VERSION ""

NS_ :

BS_:

BU_: Others VCU
VAL_TABLE_ TMSTATUS1_6B7_Hill_Stop 1 "enable" 0 "disable" ;
VAL_TABLE_ VCUTMComd_0B35_Current_Gear 4 "空挡" 2 "倒挡" 1 "前进挡" ;
VAL_TABLE_ VCUTMComd_0B2_Foot_Brake 1 "有效" 0 "无效" ;
VAL_TABLE_ VCUTMComd_0B1_HandBrake 1 "有效" 0 "无效" ;
VAL_TABLE_ TMSTATUS2_7B_TMState 511 "无效" 254 "异常" 4 "准备状态" 3 "关闭状态" 2 "发电" 1 "耗电" ;
VAL_TABLE_ TMSTATUS2_6B03_TMFailGrade 4 "严重故障" 3 "比较严重故障" 2 "故障" 1 "警告故障" 0 "无故障" ;
VAL_TABLE_ TMSTATUS1_7B03_TMMCUWorkMode 8 "错误" 7 "下弱电" 6 "主动放电" 5 "电机转矩闭环运行" 4 "电机转速闭环运行" 3 "电机允许运行" 2 "预留" 1 "低压上电正常" 0 "初始化" ;
VAL_TABLE_ TMSTATUS1_6B6_TMIGBTEnable 1 "enable" 0 "disable" ;
VAL_TABLE_ TMSTATUS1_6B5_TMActiveDisCharge 1 "enable" 0 "disable" ;
VAL_TABLE_ TMSTATUS1_6B4_TMPrechargeAllow 1 "enable" 0 "disable" ;
VAL_TABLE_ VCUTMComd_1B23_TMWorkMode 17 "Active DisCharge" 16 "TorQue Control" 1 "Speed Control" 0 "Standby" ;
VAL_TABLE_ VCUTMComd_1B1_TMFaultReset 1 "enable" 0 "disable" ;
VAL_TABLE_ VCUTMComd_1B0_TMMCUEnable 1 "enable" 0 "disable" ;
VAL_TABLE_ VCUTMComd_0B67_TMCtrlMode 17 "Description for the value '0x1F'" 16 "Braking" 1 "Drive" 0 "Free" ;
VAL_TABLE_ RefOrd_2B_TMProINF 1 "ON_Refer" 0 "OFF_Refer" ;
VAL_TABLE_ RefOrd_0B1_TMProductionINF 1 "ON_Refer" 0 "OFF_Refer" ;
VAL_TABLE_ TMProMsg2_67B_RatedPower 65535 "无效" 65534 "异常" ;
VAL_TABLE_ TMProMsg2_45B_RatedTorq 65535 "无效" 65534 "异常" ;
VAL_TABLE_ TMProMsg2_23B_PeakTorq 65535 "无效" 65534 "异常" ;
VAL_TABLE_ TMProMsg2_01B_TMMaxSpd 65535 "无效" 65534 "异常" ;
VAL_TABLE_ TMProMsg1_6B_TypeOfCooling 255 "其他方式" 2 "风冷" 1 "水冷" ;
VAL_TABLE_ TMProMsg1_45B_PeakPower 65535 "无效" 65534 "异常" ;
VAL_TABLE_ TMProMsg1_23B_MaxWorkingCur 65535 "无效" 65534 "异常" ;
VAL_TABLE_ TMProMsg1_01B_RatedVoltage 65535 "无效" 65534 "异常" ;

BO_ 3221225472 VECTOR__INDEPENDENT_SIG_MSG: 0 Vector__XXX
 SG_ RefOrd_0B1_Data_valid_Flag : 0|1@1+ (1,0) [0|0] "" Vector__XXX
 SG_ RefOrd_37B_Reserve : 0|40@1+ (1,0) [0|0] "" Vector__XXX
 SG_ RefOrd_1B : 0|8@1+ (1,0) [0|0] "" Vector__XXX
 SG_ SAS1_1B_SAS_Steering_Angle_HByte : 0|8@1+ (1,0) [0|0] "" Vector__XXX

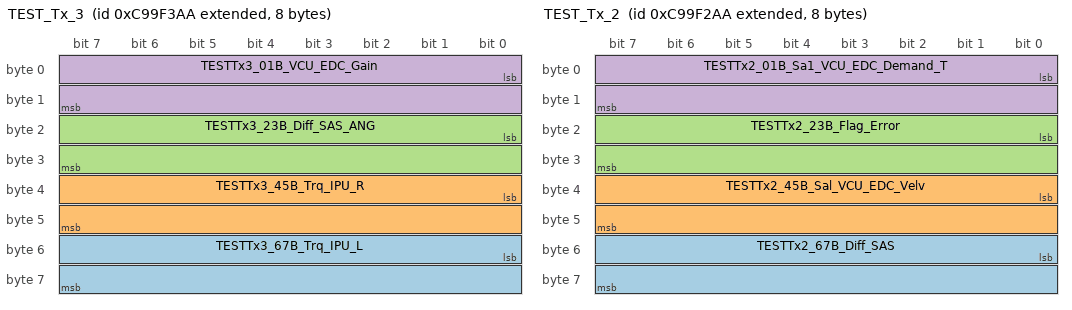
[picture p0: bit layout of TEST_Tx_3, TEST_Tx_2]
BO_ 2358899626 TEST_Tx_3: 8 Others
 SG_ TESTTx3_67B_Trq_IPU_L : 48|16@1+ (1,-5000) [0|0] "" Vector__XXX
 SG_ TESTTx3_45B_Trq_IPU_R : 32|16@1+ (1,-5000) [0|0] "" Vector__XXX
 SG_ TESTTx3_23B_Diff_SAS_ANG : 16|16@1- (1,0) [0|0] "" Vector__XXX
 SG_ TESTTx3_01B_VCU_EDC_Gain : 0|16@1+ (0.01,0) [0|0] "" Vector__XXX

BO_ 2358899370 TEST_Tx_2: 8 Others
 SG_ TESTTx2_67B_Diff_SAS : 48|16@1+ (1,0) [0|0] "" Vector__XXX
 SG_ TESTTx2_45B_Sal_VCU_EDC_Velv : 32|16@1+ (0.1,0) [0|0] "" Vector__XXX
 SG_ TESTTx2_23B_Flag_Error : 16|16@1+ (1,0) [0|0] "" Vector__XXX
 SG_ TESTTx2_01B_Sa1_VCU_EDC_Demand_T : 0|16@1+ (1,0) [0|0] "" Vector__XXX

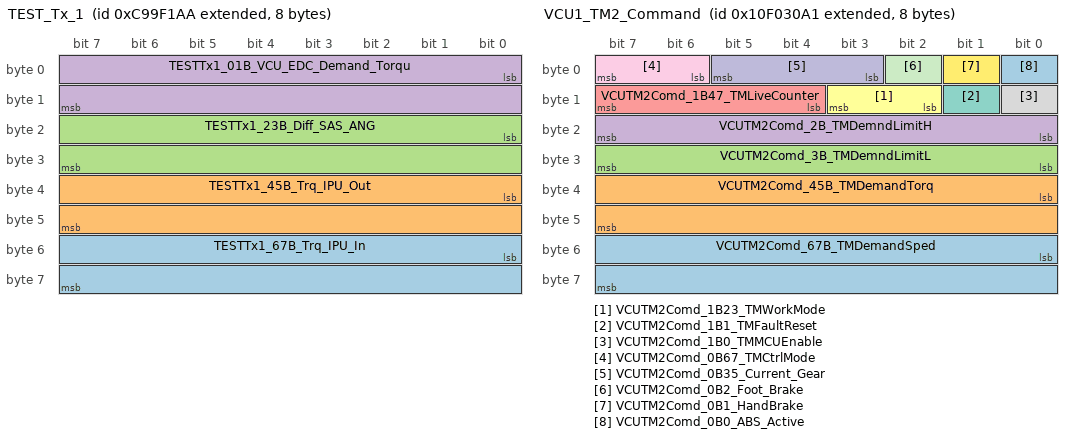
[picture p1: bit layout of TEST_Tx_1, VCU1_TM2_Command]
BO_ 2358899114 TEST_Tx_1: 8 Others
 SG_ TESTTx1_67B_Trq_IPU_In : 48|16@1- (1,0) [0|0] "" Vector__XXX
 SG_ TESTTx1_45B_Trq_IPU_Out : 32|16@1- (1,0) [0|0] "" Vector__XXX
 SG_ TESTTx1_23B_Diff_SAS_ANG : 16|16@1+ (1,0) [0|0] "" Vector__XXX
 SG_ TESTTx1_01B_VCU_EDC_Demand_Torqu : 0|16@1- (1,0) [0|0] "" Vector__XXX

BO_ 2431660193 VCU1_TM2_Command: 8 VCU
 SG_ VCUTM2Comd_67B_TMDemandSped : 48|16@1+ (1,-15000) [-15000|15000] "" Vector__XXX
 SG_ VCUTM2Comd_45B_TMDemandTorq : 32|16@1+ (1,-5000) [-5000|5000] "" Vector__XXX
 SG_ VCUTM2Comd_3B_TMDemndLimitL : 24|8@1+ (20,0) [0|5000] "rpm" Vector__XXX
 SG_ VCUTM2Comd_2B_TMDemndLimitH : 16|8@1+ (20,0) [0|5000] "rpm" Vector__XXX
 SG_ VCUTM2Comd_1B47_TMLiveCounter : 12|4@1+ (1,0) [0|0] "" Vector__XXX
 SG_ VCUTM2Comd_1B23_TMWorkMode : 10|2@1+ (1,0) [0|0] "" Vector__XXX
 SG_ VCUTM2Comd_1B1_TMFaultReset : 9|1@1+ (1,0) [0|0] "" Vector__XXX
 SG_ VCUTM2Comd_1B0_TMMCUEnable : 8|1@1+ (1,0) [0|0] "" Vector__XXX
 SG_ VCUTM2Comd_0B67_TMCtrlMode : 6|2@1+ (1,0) [0|0] "" Vector__XXX
 SG_ VCUTM2Comd_0B35_Current_Gear : 3|3@1+ (1,0) [0|0] "" Vector__XXX
 SG_ VCUTM2Comd_0B2_Foot_Brake : 2|1@1+ (1,0) [0|0] "" Vector__XXX
 SG_ VCUTM2Comd_0B1_HandBrake : 1|1@1+ (1,0) [0|0] "" Vector__XXX
 SG_ VCUTM2Comd_0B0_ABS_Active : 0|1@1+ (1,0) [0|0] "" Vector__XXX

BO_ 2565878949 TM2_STATUS_4: 8 Others
 SG_ TM2STATUS4_23B15_Inside_LVPower_ : 31|1@1+ (1,0) [0|0] "" Vector__XXX
 SG_ TM2STATUS4_23B14_Inverter_TS_War : 30|1@1+ (1,0) [0|0] "" Vector__XXX
 SG_ TM2STATUS4_23B13_Winding_TS_Warn : 29|1@1+ (1,0) [0|0] "" Vector__XXX
 SG_ TM2STATUS5_7B_MCUCode : 56|8@1+ (1,0) [0|0] "" Vector__XXX
 SG_ TM2STATUS4_5B0_Compel_field_weak : 40|1@1+ (1,0) [0|0] "" Vector__XXX
 SG_ TM2STATUS4_4B3_StallTemper_Torqu : 35|1@1+ (1,0) [0|0] "" Vector__XXX
 SG_ TM2STATUS4_4B2_ModuleTemper_Torq : 34|1@1+ (1,0) [0|0] "" Vector__XXX
 SG_ TM2STATUS4_4B1_MotorTemper_Torqu : 33|1@1+ (1,0) [0|0] "" Vector__XXX
 SG_ TM2STATUS4_4B0_HSpeed_TorqueLimi : 32|1@1+ (1,0) [0|0] "" Vector__XXX
 SG_ TM2STATUS4_23B9_EEPROM_Error : 25|1@1+ (1,0) [0|0] "" Vector__XXX
 SG_ TM2STATUS4_23B8_DC_Hall_Error : 24|1@1+ (1,0) [0|0] "" Vector__XXX
 SG_ TM2STATUS4_23B7_RDC_Dos_Warnning : 23|1@1+ (1,0) [0|0] "" Vector__XXX
 SG_ TM2STATUS4_23B6_RDC_Lot_Warnning : 22|1@1+ (1,0) [0|0] "" Vector__XXX
 SG_ TM2STATUS4_23B5_Output_ShortCut_ : 21|1@1+ (1,0) [0|0] "" Vector__XXX
 SG_ TM2STATUS4_23B4_OverLoad_Warnnin : 20|1@1+ (1,0) [0|0] "" Vector__XXX
 SG_ TM2STATUS4_23B3_Rotor_Lock_Warnn : 19|1@1+ (1,0) [0|0] "" Vector__XXX
 SG_ TM2STATUS4_23B2_Speed_High_Warnn : 18|1@1+ (1,0) [0|0] "" Vector__XXX
 SG_ TM2STATUS4_23B1_IGBT_Temp_Warnni : 17|1@1+ (1,0) [0|0] "" Vector__XXX
 SG_ TM2STATUS4_23B12_Bus_LV_Warning : 28|1@1+ (1,0) [0|0] "" Vector__XXX
 SG_ TM2STATUS4_23B11_Bus_OV_Warning : 27|1@1+ (1,0) [0|0] "" Vector__XXX
 SG_ TM2STATUS4_23B10_LowPowerSupply_ : 26|1@1+ (1,0) [0|0] "" Vector__XXX
 SG_ TM2STATUS4_23B0_Motor_Temp_Warnn : 16|1@1+ (1,0) [0|0] "" Vector__XXX
 SG_ TM2STATUS4_01B9_Bus_LV_Fault : 15|1@1+ (1,0) [0|0] "" Vector__XXX
 SG_ TM2STATUS4_01B8_Bus_OV_Fault : 14|1@1+ (1,0) [0|0] "" Vector__XXX
 SG_ TM2STATUS4_01B7_RDC_Fault : 13|1@1+ (1,0) [0|0] "" Vector__XXX
 SG_ TM2STATUS4_01B6_LosePhase_Fault : 12|1@1+ (1,0) [0|0] "" Vector__XXX
 SG_ TM2STATUS4_01B5_IGBT_W_Fault : 11|1@1+ (1,0) [0|0] "" Vector__XXX
 SG_ TM2STATUS4_01B4_IGBT_V_Fault : 10|1@1+ (1,0) [0|0] "" Vector__XXX
 SG_ TM2STATUS4_01B3_IGBT_U_Fault : 9|1@1+ (1,0) [0|0] "" Vector__XXX
 SG_ TM2STATUS4_01B2_Output_Over_Curr : 8|1@1+ (1,0) [0|0] "" Vector__XXX
 SG_ TM2STATUS4_01B1_HD_Driver_OC : 7|1@1+ (1,0) [0|0] "" Vector__XXX
 SG_ TM2STATUS4_01B15_Can_Error : 6|1@1+ (1,0) [0|0] "" Vector__XXX
 SG_ TM2STATUS4_01B14_AC_Hall_Fault : 5|1@1+ (1,0) [0|0] "" Vector__XXX
 SG_ TM2STATUS4_01B13_Water_Over_Temp : 4|1@1+ (1,0) [0|0] "" Vector__XXX
 SG_ TM2STATUS4_01B12_IGBT_Over_Temp : 3|1@1+ (1,0) [0|0] "" Vector__XXX
 SG_ TM2STATUS4_01B11_Motor_Over_Temp : 2|1@1+ (1,0) [0|0] "" Vector__XXX
 SG_ TM2STATUS4_01B10_Over_Speed : 1|1@1+ (1,0) [0|0] "" Vector__XXX
 SG_ TM2STATUS4_01B0_HD_Driver_Fault : 0|1@1+ (1,0) [0|0] "" Vector__XXX

BO_ 2565878693 TM2_STATUS_3: 8 Others
 SG_ TM2STATUS3_7B_TMErrorCode : 56|8@1+ (1,0) [0|0] "" Vector__XXX
 SG_ TM2STATUS3_6B_TMMotRotaCount : 48|8@1+ (1,0) [0|0] "" Vector__XXX
 SG_ TM2STATUS3_45B_TMMCUBUSVol : 32|16@1+ (0.1,0) [0|0] "" Vector__XXX
 SG_ TM2STATUS3_23B_TMMCUBUSCur : 16|16@1+ (0.1,-800) [0|0] "" Vector__XXX
 SG_ TM2STATUS3_1B7_Reserve : 15|1@1+ (1,0) [0|0] "" Vector__XXX
 SG_ TM2STATUS3_1B6_TMWarnOV : 14|1@1+ (1,0) [0|0] "" Vector__XXX
 SG_ TM2STATUS3_1B5_TMWarnUV : 13|1@1+ (1,0) [0|0] "" Vector__XXX
 SG_ TM2STATUS3_1B4_TMWarnWindOT : 12|1@1+ (1,0) [0|0] "" Vector__XXX
 SG_ TM2STATUS3_1B3_TMEWarnInerOt : 11|1@1+ (1,0) [0|0] "" Vector__XXX
 SG_ TM2STATUS3_1B2_TMError24VUV : 10|1@1+ (1,0) [0|0] "" Vector__XXX
 SG_ TM2STATUS3_1B1_TMErrorUV : 9|1@1+ (1,0) [0|0] "" Vector__XXX
 SG_ TM2STATUS3_1B0_TMErrorITM : 8|1@1+ (1,0) [0|0] "" Vector__XXX
 SG_ TM2STATUS3_0B7_TMErrorCAN : 7|1@1+ (1,0) [0|0] "" Vector__XXX
 SG_ TM2STATUS3_0B6_TMErrorWindingTS : 6|1@1+ (1,0) [0|0] "" Vector__XXX
 SG_ TM2STATUS3_0B5_TMErrorResolver : 5|1@1+ (1,0) [0|0] "" Vector__XXX
 SG_ TM2STATUS3_0B4_TMErrorInverterOT : 4|1@1+ (1,0) [0|0] "" Vector__XXX
 SG_ TM2STATUS3_0B3_TMErrorWindingOT : 3|1@1+ (1,0) [0|0] "" Vector__XXX
 SG_ TM2STATUS3_0B2_TMError0S : 2|1@1+ (1,0) [0|0] "" Vector__XXX
 SG_ TM2STATUS3_0B1_TMError0C : 1|1@1+ (1,0) [0|0] "" Vector__XXX
 SG_ TM2STATUS3_0B0_TMError0V : 0|1@1+ (1,0) [0|0] "" Vector__XXX

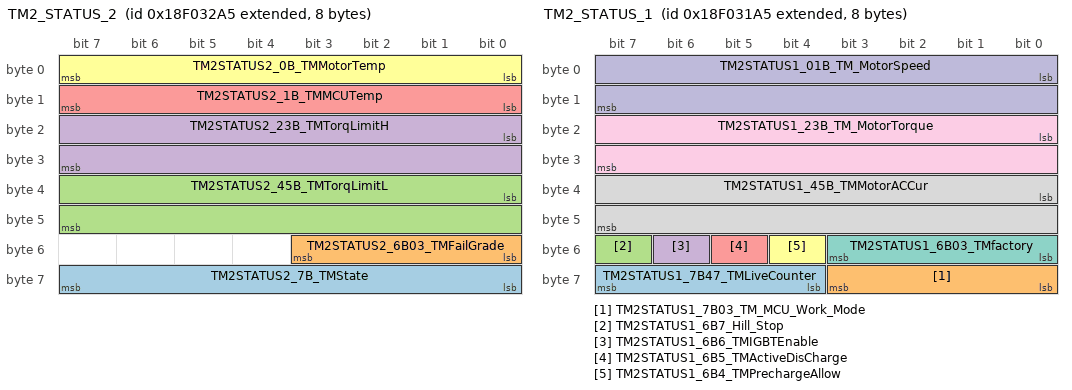
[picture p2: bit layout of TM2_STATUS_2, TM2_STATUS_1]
BO_ 2565878437 TM2_STATUS_2: 8 Others
 SG_ TM2STATUS2_7B_TMState : 56|8@1+ (1,0) [0|0] "" Vector__XXX
 SG_ TM2STATUS2_6B03_TMFailGrade : 48|4@1+ (1,0) [0|0] "" Vector__XXX
 SG_ TM2STATUS2_45B_TMTorqLimitL : 32|16@1+ (1,-5000) [0|0] "" Vector__XXX
 SG_ TM2STATUS2_23B_TMTorqLimitH : 16|16@1+ (1,0) [0|5000] "" Vector__XXX
 SG_ TM2STATUS2_1B_TMMCUTemp : 8|8@1+ (1,-40) [0|0] "" Vector__XXX
 SG_ TM2STATUS2_0B_TMMotorTemp : 0|8@1+ (1,-40) [0|0] "" Vector__XXX

BO_ 2565878181 TM2_STATUS_1: 8 Others
 SG_ TM2STATUS1_7B47_TMLiveCounter : 60|4@1+ (1,0) [0|15] "" Vector__XXX
 SG_ TM2STATUS1_7B03_TM_MCU_Work_Mode : 56|4@1+ (1,0) [0|0] "" Vector__XXX
 SG_ TM2STATUS1_6B7_Hill_Stop : 55|1@1+ (1,0) [0|0] "" Vector__XXX
 SG_ TM2STATUS1_6B6_TMIGBTEnable : 54|1@1+ (1,0) [0|0] "" Vector__XXX
 SG_ TM2STATUS1_6B5_TMActiveDisCharge : 53|1@1+ (1,0) [0|0] "" Vector__XXX
 SG_ TM2STATUS1_6B4_TMPrechargeAllow : 52|1@1+ (1,0) [0|0] "" Vector__XXX
 SG_ TM2STATUS1_6B03_TMfactory : 48|4@1+ (1,0) [0|0] "" Vector__XXX
 SG_ TM2STATUS1_45B_TMMotorACCur : 32|16@1+ (0.1,0) [0|0] "A" Vector__XXX
 SG_ TM2STATUS1_23B_TM_MotorTorque : 16|16@1+ (1,-5000) [0|0] "" Vector__XXX
 SG_ TM2STATUS1_01B_TM_MotorSpeed : 0|16@1+ (1,-15000) [0|0] "" Vector__XXX

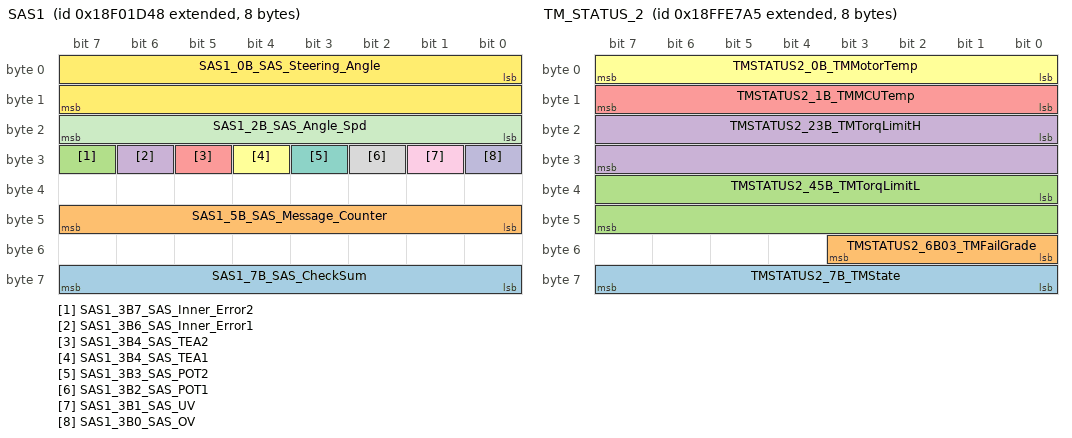
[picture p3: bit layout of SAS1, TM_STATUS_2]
BO_ 2565872968 SAS1: 8 Others
 SG_ SAS1_7B_SAS_CheckSum : 56|8@1+ (1,0) [0|255] "" Vector__XXX
 SG_ SAS1_5B_SAS_Message_Counter : 40|8@1+ (1,0) [0|0] "" Vector__XXX
 SG_ SAS1_3B7_SAS_Inner_Error2 : 31|1@1+ (1,0) [0|0] "" Vector__XXX
 SG_ SAS1_3B6_SAS_Inner_Error1 : 30|1@1+ (1,0) [0|0] "" Vector__XXX
 SG_ SAS1_3B4_SAS_TEA2 : 29|1@1+ (1,0) [0|0] "" Vector__XXX
 SG_ SAS1_3B4_SAS_TEA1 : 28|1@1+ (1,0) [0|0] "" Vector__XXX
 SG_ SAS1_3B3_SAS_POT2 : 27|1@1+ (1,0) [0|0] "" Vector__XXX
 SG_ SAS1_3B2_SAS_POT1 : 26|1@1+ (1,0) [0|0] "" Vector__XXX
 SG_ SAS1_3B1_SAS_UV : 25|1@1+ (1,0) [0|0] "" Vector__XXX
 SG_ SAS1_3B0_SAS_OV : 24|1@1+ (1,0) [0|0] "" Vector__XXX
 SG_ SAS1_2B_SAS_Angle_Spd : 16|8@1+ (4,0) [0|1020] "" Vector__XXX
 SG_ SAS1_0B_SAS_Steering_Angle : 0|16@1- (0.1,0) [0|0] "" Vector__XXX

BO_ 2566908325 TM_STATUS_4: 8 Others
 SG_ TMSTATUS4_23B15_Inside_LVPower_E : 31|1@1+ (1,0) [0|0] "" Vector__XXX
 SG_ TMSTATUS4_23B14_Inverter_TS_Warn : 30|1@1+ (1,0) [0|0] "" Vector__XXX
 SG_ TMSTATUS4_23B13_Winding_TS_Warni : 29|1@1+ (1,0) [0|0] "" Vector__XXX
 SG_ TMSTATUS4_7B_MCUCode : 56|8@1+ (1,0) [0|0] "" Vector__XXX
 SG_ TMSTATUS4_5B0_Compel_field_weake : 40|1@1+ (1,0) [0|0] "" Vector__XXX
 SG_ TMSTATUS4_4B3_StallTemper_Torque : 35|1@1+ (1,0) [0|0] "" Vector__XXX
 SG_ TMSTATUS4_4B2_ModuleTemper_Torqu : 34|1@1+ (1,0) [0|0] "" Vector__XXX
 SG_ TMSTATUS4_4B1_MotorTemper_Torque : 33|1@1+ (1,0) [0|0] "" Vector__XXX
 SG_ TMSTATUS4_4B0_HSpeed_TorqueLimit : 32|1@1+ (1,0) [0|0] "" Vector__XXX
 SG_ TMSTATUS4_23B9_EEPROM_Error : 25|1@1+ (1,0) [0|0] "" Vector__XXX
 SG_ TMSTATUS4_23B8_DC_Hall_Error : 24|1@1+ (1,0) [0|0] "" Vector__XXX
 SG_ TMSTATUS4_23B7_RDC_Dos_Warnning : 23|1@1+ (1,0) [0|0] "" Vector__XXX
 SG_ TMSTATUS4_23B6_RDC_Lot_Warnning : 22|1@1+ (1,0) [0|0] "" Vector__XXX
 SG_ TMSTATUS4_23B5_Output_ShortCut_W : 21|1@1+ (1,0) [0|0] "" Vector__XXX
 SG_ TMSTATUS4_23B4_OverLoad_Warnning : 20|1@1+ (1,0) [0|0] "" Vector__XXX
 SG_ TMSTATUS4_23B3_Rotor_Lock_Warnni : 19|1@1+ (1,0) [0|0] "" Vector__XXX
 SG_ TMSTATUS4_23B2_Speed_High_Warnni : 18|1@1+ (1,0) [0|0] "" Vector__XXX
 SG_ TMSTATUS4_23B1_IGBT_Temp_Warnnin : 17|1@1+ (1,0) [0|0] "" Vector__XXX
 SG_ TMSTATUS4_23B12_Bus_LV_Warning : 28|1@1+ (1,0) [0|0] "" Vector__XXX
 SG_ TMSTATUS4_23B11_Bus_OV_Warning : 27|1@1+ (1,0) [0|0] "" Vector__XXX
 SG_ TMSTATUS4_23B10_LowPowerSupply_E : 26|1@1+ (1,0) [0|0] "" Vector__XXX
 SG_ TMSTATUS4_23B0_Motor_Temp_Warnni : 16|1@1+ (1,0) [0|0] "" Vector__XXX
 SG_ TMSTATUS4_01B9_Bus_LV_Fault : 9|1@1+ (1,0) [0|0] "" Vector__XXX
 SG_ TMSTATUS4_01B8_Bus_OV_Fault : 8|1@1+ (1,0) [0|0] "" Vector__XXX
 SG_ TMSTATUS4_01B7_RDC_Fault : 7|1@1+ (1,0) [0|0] "" Vector__XXX
 SG_ TMSTATUS4_01B6_LosePhase_Fault : 6|1@1+ (1,0) [0|0] "" Vector__XXX
 SG_ TMSTATUS4_01B5_IGBT_W_Fault : 5|1@1+ (1,0) [0|0] "" Vector__XXX
 SG_ TMSTATUS4_01B4_IGBT_V_Fault : 4|1@1+ (1,0) [0|0] "" Vector__XXX
 SG_ TMSTATUS4_01B3_IGBT_U_Fault : 3|1@1+ (1,0) [0|0] "" Vector__XXX
 SG_ TMSTATUS4_01B2_Output_Over_Curre : 2|1@1+ (1,0) [0|0] "" Vector__XXX
 SG_ TMSTATUS4_01B1_HD_Driver_OC : 1|1@1+ (1,0) [0|0] "" Vector__XXX
 SG_ TMSTATUS4_01B15_Can_Error : 15|1@1+ (1,0) [0|0] "" Vector__XXX
 SG_ TMSTATUS4_01B14_AC_Hall_Fault : 14|1@1+ (1,0) [0|0] "" Vector__XXX
 SG_ TMSTATUS4_01B13_Water_Over_Temp : 13|1@1+ (1,0) [0|0] "" Vector__XXX
 SG_ TMSTATUS4_01B12_IGBT_Over_Temp : 12|1@1+ (1,0) [0|0] "" Vector__XXX
 SG_ TMSTATUS4_01B11_Motor_Over_Temp : 11|1@1+ (1,0) [0|0] "" Vector__XXX
 SG_ TMSTATUS4_01B10_Over_Speed : 10|1@1+ (1,0) [0|0] "" Vector__XXX
 SG_ TMSTATUS4_01B0_HD_Driver_Fault : 0|1@1+ (1,0) [0|0] "" Vector__XXX

BO_ 2566908069 TM_STATUS_3: 8 Others
 SG_ TMSTATUS3_0B2_TMError0S : 2|1@1+ (1,0) [0|0] "" Vector__XXX
 SG_ TMSTATUS3_7B_TMErrorCode : 56|8@1+ (1,0) [0|0] "" Vector__XXX
 SG_ TMSTATUS3_6B_TMMotRotaCount : 48|8@1+ (1,0) [0|0] "" Vector__XXX
 SG_ TMSTATUS3_45B_TMMCUBUSVol : 32|16@1+ (0.1,0) [0|0] "" Vector__XXX
 SG_ TMSTATUS3_23B_TMMCUBUSCur : 16|16@1- (0.1,-800) [0|0] "" Vector__XXX
 SG_ TMSTATUS3_1B7_Reserve : 15|1@1+ (1,0) [0|0] "" Vector__XXX
 SG_ TMSTATUS3_1B6_TMWarnOV : 14|1@1+ (1,0) [0|0] "" Vector__XXX
 SG_ TMSTATUS3_1B5_TMWarnUV : 13|1@1+ (1,0) [0|0] "" Vector__XXX
 SG_ TMSTATUS3_1B4_TMWarnWindOT : 12|1@1+ (1,0) [0|0] "" Vector__XXX
 SG_ TMSTATUS3_1B3_TMEWarnInerOt : 11|1@1+ (1,0) [0|0] "" Vector__XXX
 SG_ TMSTATUS3_1B2_TMError24VUV : 10|1@1+ (1,0) [0|0] "" Vector__XXX
 SG_ TMSTATUS3_1B1_TMErrorUV : 9|1@1+ (1,0) [0|0] "" Vector__XXX
 SG_ TMSTATUS3_1B0_TMErrorITM : 8|1@1+ (1,0) [0|0] "" Vector__XXX
 SG_ TMSTATUS3_0B7_TMErrorCAN : 7|1@1+ (1,0) [0|0] "" Vector__XXX
 SG_ TMSTATUS3_0B6_TMErrorWindingTS : 6|1@1+ (1,0) [0|0] "" Vector__XXX
 SG_ TMSTATUS3_0B5_TMErrorResolver : 5|1@1+ (1,0) [0|0] "" Vector__XXX
 SG_ TMSTATUS3_0B4_TMErrorInverterOT : 4|1@1+ (1,0) [0|0] "" Vector__XXX
 SG_ TMSTATUS3_0B3_TMErrorWindingOT : 3|1@1+ (1,0) [0|0] "" Vector__XXX
 SG_ TMSTATUS3_0B1_TMError0C : 1|1@1+ (1,0) [0|0] "" Vector__XXX
 SG_ TMSTATUS3_0B0_TMError0V : 0|1@1+ (1,0) [0|0] "" Vector__XXX

BO_ 2566907813 TM_STATUS_2: 8 Others
 SG_ TMSTATUS2_7B_TMState : 56|8@1+ (1,0) [0|0] "" Vector__XXX
 SG_ TMSTATUS2_6B03_TMFailGrade : 48|4@1+ (1,0) [0|0] "" Vector__XXX
 SG_ TMSTATUS2_45B_TMTorqLimitL : 32|16@1+ (1,-5000) [0|0] "" Vector__XXX
 SG_ TMSTATUS2_23B_TMTorqLimitH : 16|16@1+ (1,0) [0|5000] "" Vector__XXX
 SG_ TMSTATUS2_1B_TMMCUTemp : 8|8@1+ (1,-40) [0|0] "" Vector__XXX
 SG_ TMSTATUS2_0B_TMMotorTemp : 0|8@1+ (1,-40) [0|0] "" Vector__XXX

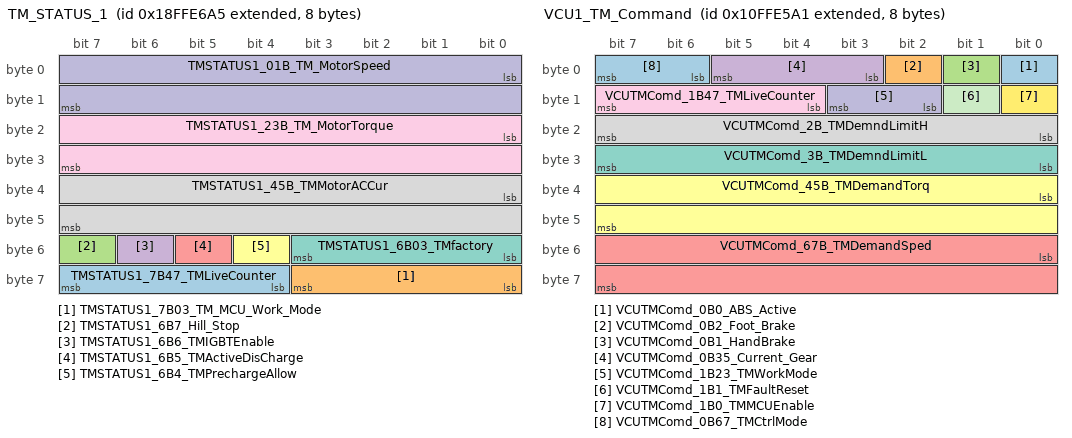
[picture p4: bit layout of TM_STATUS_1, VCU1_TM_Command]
BO_ 2566907557 TM_STATUS_1: 8 Others
 SG_ TMSTATUS1_7B47_TMLiveCounter : 60|4@1+ (1,0) [0|15] "" Vector__XXX
 SG_ TMSTATUS1_7B03_TM_MCU_Work_Mode : 56|4@1+ (1,0) [0|0] "" Vector__XXX
 SG_ TMSTATUS1_6B7_Hill_Stop : 55|1@1+ (1,0) [0|0] "" Vector__XXX
 SG_ TMSTATUS1_6B6_TMIGBTEnable : 54|1@1+ (1,0) [0|0] "" Vector__XXX
 SG_ TMSTATUS1_6B5_TMActiveDisCharge : 53|1@1+ (1,0) [0|0] "" Vector__XXX
 SG_ TMSTATUS1_6B4_TMPrechargeAllow : 52|1@1+ (1,0) [0|0] "" Vector__XXX
 SG_ TMSTATUS1_6B03_TMfactory : 48|4@1+ (1,0) [0|0] "" Vector__XXX
 SG_ TMSTATUS1_45B_TMMotorACCur : 32|16@1+ (0.1,0) [0|0] "A" Vector__XXX
 SG_ TMSTATUS1_23B_TM_MotorTorque : 16|16@1+ (1,-5000) [0|0] "" Vector__XXX
 SG_ TMSTATUS1_01B_TM_MotorSpeed : 0|16@1+ (1,-15000) [0|0] "" Vector__XXX

BO_ 2432689569 VCU1_TM_Command: 8 VCU
 SG_ VCUTMComd_0B0_ABS_Active : 0|1@1+ (1,0) [0|0] "" Vector__XXX
 SG_ VCUTMComd_0B2_Foot_Brake : 2|1@1+ (1,0) [0|0] "" Vector__XXX
 SG_ VCUTMComd_0B1_HandBrake : 1|1@1+ (1,0) [0|0] "" Vector__XXX
 SG_ VCUTMComd_0B35_Current_Gear : 3|3@1+ (1,0) [0|0] "" Vector__XXX
 SG_ VCUTMComd_67B_TMDemandSped : 48|16@1+ (1,-15000) [-15000|15000] "" Vector__XXX
 SG_ VCUTMComd_45B_TMDemandTorq : 32|16@1+ (1,-5000) [-5000|5000] "" Vector__XXX
 SG_ VCUTMComd_3B_TMDemndLimitL : 24|8@1+ (20,0) [0|5000] "rpm" Vector__XXX
 SG_ VCUTMComd_2B_TMDemndLimitH : 16|8@1+ (20,0) [0|5000] "rpm" Vector__XXX
 SG_ VCUTMComd_1B47_TMLiveCounter : 12|4@1+ (1,0) [0|0] "" Vector__XXX
 SG_ VCUTMComd_1B23_TMWorkMode : 10|2@1+ (1,0) [0|0] "" Vector__XXX
 SG_ VCUTMComd_1B1_TMFaultReset : 9|1@1+ (1,0) [0|0] "" Vector__XXX
 SG_ VCUTMComd_1B0_TMMCUEnable : 8|1@1+ (1,0) [0|0] "" Vector__XXX
 SG_ VCUTMComd_0B67_TMCtrlMode : 6|2@1+ (1,0) [0|0] "" Vector__XXX

BO_ 2566815905 Refer_Order: 9 Others
 SG_ RefOrd_2B_TM_Production_INF : 16|8@1+ (1,0) [0|0] "" Vector__XXX
 SG_ RefOrd_0B1_TMProductionINF : 1|1@1+ (1,0) [0|0] "" Vector__XXX

BO_ 2565874341 TM_Production_INF3: 8 Others
 SG_ TMProMsg3_07B_TMSerialNum : 0|64@1+ (1,0) [0|0] "" Vector__XXX

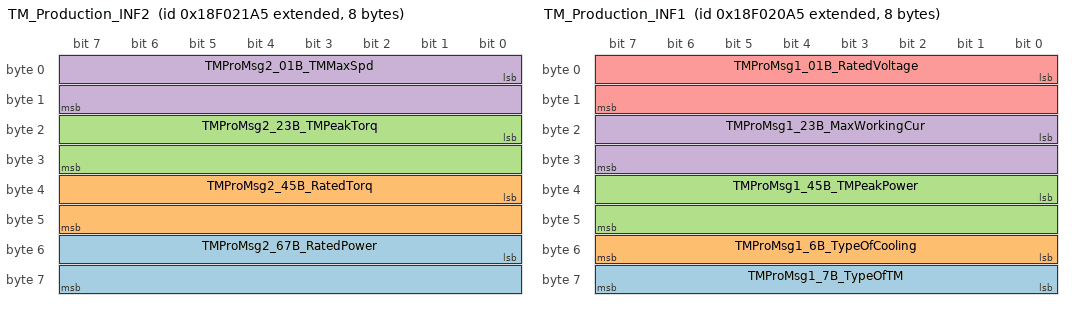
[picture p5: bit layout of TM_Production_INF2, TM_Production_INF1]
BO_ 2565874085 TM_Production_INF2: 8 Others
 SG_ TMProMsg2_67B_RatedPower : 48|16@1+ (1,0) [0|6000] "KW" Vector__XXX
 SG_ TMProMsg2_45B_RatedTorq : 32|16@1+ (0.1,-2000) [-2000|4553.1] "N*m" Vector__XXX
 SG_ TMProMsg2_23B_TMPeakTorq : 16|16@1+ (0.1,-2000) [-2000|4553.1] "N*m" Vector__XXX
 SG_ TMProMsg2_01B_TMMaxSpd : 0|16@1+ (1,-20000) [-20000|45531] "r/min" Vector__XXX

BO_ 2565873829 TM_Production_INF1: 8 Others
 SG_ TMProMsg1_7B_TypeOfTM : 56|8@1+ (1,0) [0|0] "" Vector__XXX
 SG_ TMProMsg1_6B_TypeOfCooling : 48|8@1+ (1,0) [0|0] "KW" Vector__XXX
 SG_ TMProMsg1_45B_TMPeakPower : 32|16@1+ (1,0) [0|6000] "KW" Vector__XXX
 SG_ TMProMsg1_23B_MaxWorkingCur : 16|16@1+ (0.1,-1000) [0|0] "A" Vector__XXX
 SG_ TMProMsg1_01B_RatedVoltage : 0|16@1+ (0.1,0) [0|6000] "V" Vector__XXX

CM_ BO_ 3221225472 "This is a message for not used signals, created by Vector CANdb++ DBC OLE DB Provider.";
BA_DEF_ SG_  "SigType" ENUM  "Default","Range","RangeSigned","ASCII","Discrete","Control","ReferencePGN","DTC","StringDelimiter","StringLength","StringLengthControl";
BA_DEF_ SG_  "GenSigEVName" STRING ;
BA_DEF_ SG_  "GenSigILSupport" ENUM  "Yes","No";
BA_DEF_ SG_  "GenSigSendType" ENUM  "Cyclic","OnWrite","reserved","OnChange","reserved","reserved","reserved","NoSigSendType";
BA_DEF_ SG_  "GenSigStartValue" INT 0 10000;
BA_DEF_ BO_  "GenMsgILSupport" ENUM  "Yes","No";
BA_DEF_ BU_  "NmStationAddress" INT 0 255;
BA_DEF_ BO_  "GenMsgSendType" ENUM  "cyclic","reserved","cyclicIfActive","reserved","reserved","reserved","reserved","reserved","noMsgSendType";
BA_DEF_ BO_  "GenMsgRequestable" INT 0 1;
BA_DEF_  "DBName" STRING ;
BA_DEF_  "BusType" STRING ;
BA_DEF_  "ProtocolType" STRING ;
BA_DEF_ BO_  "VFrameFormat" ENUM  "StandardCAN","ExtendedCAN","reserved","J1939PG";
BA_DEF_ SG_  "SystemSignalLongSymbol" STRING ;
BA_DEF_DEF_  "SigType" "Default";
BA_DEF_DEF_  "GenSigEVName" "Env@Nodename_@Signame";
BA_DEF_DEF_  "GenSigILSupport" "Yes";
BA_DEF_DEF_  "GenSigSendType" "NoSigSendType";
BA_DEF_DEF_  "GenSigStartValue" 0;
BA_DEF_DEF_  "GenMsgILSupport" "Yes";
BA_DEF_DEF_  "NmStationAddress" 254;
BA_DEF_DEF_  "GenMsgSendType" "noMsgSendType";
BA_DEF_DEF_  "GenMsgRequestable" 1;
BA_DEF_DEF_  "DBName" "";
BA_DEF_DEF_  "BusType" "CAN";
BA_DEF_DEF_  "ProtocolType" "J1939";
BA_DEF_DEF_  "VFrameFormat" "J1939PG";
BA_DEF_DEF_  "SystemSignalLongSymbol" "";
BA_ "DBName" "KLNEVTXXY001";
BA_ "NmStationAddress" BU_ Others 0;
BA_ "NmStationAddress" BU_ VCU 161;
BA_ "VFrameFormat" BO_ 2358899626 1;
BA_ "VFrameFormat" BO_ 2358899370 1;
BA_ "VFrameFormat" BO_ 2358899114 1;
BA_ "VFrameFormat" BO_ 2565872968 1;
BA_ "GenSigStartValue" SG_ 2358899626 TESTTx3_67B_Trq_IPU_L 5000;
BA_ "GenSigStartValue" SG_ 2358899626 TESTTx3_45B_Trq_IPU_R 5000;
BA_ "SystemSignalLongSymbol" SG_ 2358899370 TESTTx2_01B_Sa1_VCU_EDC_Demand_T "TESTTx2_01B_Sa1_VCU_EDC_Demand_Torque";
BA_ "SystemSignalLongSymbol" SG_ 2358899114 TESTTx1_01B_VCU_EDC_Demand_Torqu "TESTTx1_01B_VCU_EDC_Demand_Torque";
BA_ "SystemSignalLongSymbol" SG_ 2565878949 TM2STATUS4_23B15_Inside_LVPower_ "TM2STATUS4_23B15_Inside_LVPower_Error";
BA_ "SystemSignalLongSymbol" SG_ 2565878949 TM2STATUS4_23B14_Inverter_TS_War "TM2STATUS4_23B14_Inverter_TS_Warning";
BA_ "SystemSignalLongSymbol" SG_ 2565878949 TM2STATUS4_23B13_Winding_TS_Warn "TM2STATUS4_23B13_Winding_TS_Warning";
BA_ "SystemSignalLongSymbol" SG_ 2565878949 TM2STATUS4_5B0_Compel_field_weak "TM2STATUS4_5B0_Compel_field_weakening";
BA_ "SystemSignalLongSymbol" SG_ 2565878949 TM2STATUS4_4B3_StallTemper_Torqu "TM2STATUS4_4B3_StallTemper_TorqueLimit";
BA_ "SystemSignalLongSymbol" SG_ 2565878949 TM2STATUS4_4B2_ModuleTemper_Torq "TM2STATUS4_4B2_ModuleTemper_TorqueLimit";
BA_ "SystemSignalLongSymbol" SG_ 2565878949 TM2STATUS4_4B1_MotorTemper_Torqu "TM2STATUS4_4B1_MotorTemper_TorqueLimit";
BA_ "SystemSignalLongSymbol" SG_ 2565878949 TM2STATUS4_4B0_HSpeed_TorqueLimi "TM2STATUS4_4B0_HSpeed_TorqueLimit";
BA_ "SystemSignalLongSymbol" SG_ 2565878949 TM2STATUS4_23B5_Output_ShortCut_ "TM2STATUS4_23B5_Output_ShortCut_Warnning";
BA_ "SystemSignalLongSymbol" SG_ 2565878949 TM2STATUS4_23B4_OverLoad_Warnnin "TM2STATUS4_23B4_OverLoad_Warnning";
BA_ "SystemSignalLongSymbol" SG_ 2565878949 TM2STATUS4_23B3_Rotor_Lock_Warnn "TM2STATUS4_23B3_Rotor_Lock_Warnning";
BA_ "SystemSignalLongSymbol" SG_ 2565878949 TM2STATUS4_23B2_Speed_High_Warnn "TM2STATUS4_23B2_Speed_High_Warnning";
BA_ "SystemSignalLongSymbol" SG_ 2565878949 TM2STATUS4_23B1_IGBT_Temp_Warnni "TM2STATUS4_23B1_IGBT_Temp_Warnning";
BA_ "SystemSignalLongSymbol" SG_ 2565878949 TM2STATUS4_23B10_LowPowerSupply_ "TM2STATUS4_23B10_LowPowerSupply_Error";
BA_ "SystemSignalLongSymbol" SG_ 2565878949 TM2STATUS4_23B0_Motor_Temp_Warnn "TM2STATUS4_23B0_Motor_Temp_Warnning";
BA_ "SystemSignalLongSymbol" SG_ 2565878949 TM2STATUS4_01B2_Output_Over_Curr "TM2STATUS4_01B2_Output_Over_Current";
BA_ "GenSigStartValue" SG_ 2565878181 TM2STATUS1_23B_TM_MotorTorque 5000;
BA_ "SystemSignalLongSymbol" SG_ 2566908325 TMSTATUS4_23B15_Inside_LVPower_E "TMSTATUS4_23B15_Inside_LVPower_Error";
BA_ "SystemSignalLongSymbol" SG_ 2566908325 TMSTATUS4_23B14_Inverter_TS_Warn "TMSTATUS4_23B14_Inverter_TS_Warning";
BA_ "SystemSignalLongSymbol" SG_ 2566908325 TMSTATUS4_23B13_Winding_TS_Warni "TMSTATUS4_23B13_Winding_TS_Warning";
BA_ "SystemSignalLongSymbol" SG_ 2566908325 TMSTATUS4_5B0_Compel_field_weake "TMSTATUS4_5B0_Compel_field_weakening";
BA_ "SystemSignalLongSymbol" SG_ 2566908325 TMSTATUS4_4B3_StallTemper_Torque "TMSTATUS4_4B3_StallTemper_TorqueLimit";
BA_ "SystemSignalLongSymbol" SG_ 2566908325 TMSTATUS4_4B2_ModuleTemper_Torqu "TMSTATUS4_4B2_ModuleTemper_TorqueLimit";
BA_ "SystemSignalLongSymbol" SG_ 2566908325 TMSTATUS4_4B1_MotorTemper_Torque "TMSTATUS4_4B1_MotorTemper_TorqueLimit";
BA_ "SystemSignalLongSymbol" SG_ 2566908325 TMSTATUS4_23B5_Output_ShortCut_W "TMSTATUS4_23B5_Output_ShortCut_Warnning";
BA_ "SystemSignalLongSymbol" SG_ 2566908325 TMSTATUS4_23B3_Rotor_Lock_Warnni "TMSTATUS4_23B3_Rotor_Lock_Warnning";
BA_ "SystemSignalLongSymbol" SG_ 2566908325 TMSTATUS4_23B2_Speed_High_Warnni "TMSTATUS4_23B2_Speed_High_Warnning";
BA_ "SystemSignalLongSymbol" SG_ 2566908325 TMSTATUS4_23B1_IGBT_Temp_Warnnin "TMSTATUS4_23B1_IGBT_Temp_Warnning";
BA_ "SystemSignalLongSymbol" SG_ 2566908325 TMSTATUS4_23B10_LowPowerSupply_E "TMSTATUS4_23B10_LowPowerSupply_Error";
BA_ "SystemSignalLongSymbol" SG_ 2566908325 TMSTATUS4_23B0_Motor_Temp_Warnni "TMSTATUS4_23B0_Motor_Temp_Warnning";
BA_ "SystemSignalLongSymbol" SG_ 2566908325 TMSTATUS4_01B2_Output_Over_Curre "TMSTATUS4_01B2_Output_Over_Current";
BA_ "GenSigStartValue" SG_ 2566907557 TMSTATUS1_23B_TM_MotorTorque 4000;
BA_ "GenSigStartValue" SG_ 2565873829 TMProMsg1_23B_MaxWorkingCur 10000;
VAL_ 2431660193 VCUTM2Comd_1B23_TMWorkMode 17 "Active DisCharge" 16 "TorQue Control" 1 "Speed Control" 0 "Standby" ;
VAL_ 2431660193 VCUTM2Comd_1B1_TMFaultReset 1 "enable" 0 "disable" ;
VAL_ 2431660193 VCUTM2Comd_1B0_TMMCUEnable 1 "enable" 0 "disable" ;
VAL_ 2431660193 VCUTM2Comd_0B67_TMCtrlMode 17 "Reversal（后退驱动）" 16 "Braking" 1 "Drive" 0 "Free" ;
VAL_ 2431660193 VCUTM2Comd_0B35_Current_Gear 4 "空挡" 2 "倒挡" 1 "前进挡" ;
VAL_ 2431660193 VCUTM2Comd_0B2_Foot_Brake 1 "有效" 0 "无效" ;
VAL_ 2431660193 VCUTM2Comd_0B1_HandBrake 1 "有效" 0 "无效" ;
VAL_ 2565878437 TM2STATUS2_7B_TMState 511 "无效" 254 "异常" 4 "准备状态" 3 "关闭状态" 2 "发电" 1 "耗电" ;
VAL_ 2565878437 TM2STATUS2_6B03_TMFailGrade 4 "严重故障" 3 "比较严重故障" 2 "故障" 1 "警告故障" 0 "无故障" ;
VAL_ 2565878181 TM2STATUS1_7B03_TM_MCU_Work_Mode 8 "错误" 7 "下弱电" 6 "主动放电" 5 "电机转矩闭环运行" 4 "电机转速闭环运行" 3 "电机允许运行" 2 "预留" 1 "低压上电正常" 0 "初始化" ;
VAL_ 2565878181 TM2STATUS1_6B7_Hill_Stop 1 "enable" 0 "disable" ;
VAL_ 2565878181 TM2STATUS1_6B6_TMIGBTEnable 1 "enable" 0 "disable" ;
VAL_ 2565878181 TM2STATUS1_6B4_TMPrechargeAllow 1 "enable" 0 "disable" ;
VAL_ 2565872968 SAS1_3B7_SAS_Inner_Error2 1 "内部错误2" 0 "正常" ;
VAL_ 2565872968 SAS1_3B6_SAS_Inner_Error1 1 "内部错误1" 0 "正常" ;
VAL_ 2565872968 SAS1_3B4_SAS_TEA2 1 "时序错误2" 0 "正常" ;
VAL_ 2565872968 SAS1_3B4_SAS_TEA1 1 "时序错误1" 0 "0" ;
VAL_ 2565872968 SAS1_3B3_SAS_POT2 1 "上电自检错误2" 0 "正常" ;
VAL_ 2565872968 SAS1_3B2_SAS_POT1 1 "上电自检错误1" 0 "正常" ;
VAL_ 2565872968 SAS1_3B1_SAS_UV 1 "电压过低" 0 "正常" ;
VAL_ 2565872968 SAS1_3B0_SAS_OV 1 "电压过高" 0 "正常" ;
VAL_ 2566907813 TMSTATUS2_7B_TMState 511 "无效" 254 "异常" 4 "准备状态" 3 "关闭状态" 2 "发电" 1 "耗电" ;
VAL_ 2566907813 TMSTATUS2_6B03_TMFailGrade 4 "严重故障" 3 "比较严重故障" 2 "故障" 1 "警告故障" 0 "无故障" ;
VAL_ 2566907557 TMSTATUS1_7B03_TM_MCU_Work_Mode 8 "错误" 7 "下弱电" 6 "主动放电" 5 "电机转矩闭环运行" 4 "电机转速闭环运行" 3 "电机允许运行" 2 "预留" 1 "低压上电正常" 0 "初始化" ;
VAL_ 2566907557 TMSTATUS1_6B7_Hill_Stop 1 "enable" 0 "disable" ;
VAL_ 2566907557 TMSTATUS1_6B6_TMIGBTEnable 1 "enable" 0 "disable" ;
VAL_ 2566907557 TMSTATUS1_6B4_TMPrechargeAllow 1 "enable" 0 "disable" ;
VAL_ 2432689569 VCUTMComd_0B2_Foot_Brake 1 "有效" 0 "无效" ;
VAL_ 2432689569 VCUTMComd_0B1_HandBrake 1 "有效" 0 "无效" ;
VAL_ 2432689569 VCUTMComd_0B35_Current_Gear 4 "空挡" 2 "倒挡" 1 "前进挡" ;
VAL_ 2432689569 VCUTMComd_1B23_TMWorkMode 17 "Active DisCharge" 16 "TorQue Control" 1 "Speed Control" 0 "Standby" ;
VAL_ 2432689569 VCUTMComd_1B1_TMFaultReset 1 "enable" 0 "disable" ;
VAL_ 2432689569 VCUTMComd_1B0_TMMCUEnable 1 "enable" 0 "disable" ;
VAL_ 2432689569 VCUTMComd_0B67_TMCtrlMode 17 "Reversal（后退驱动）" 16 "Braking" 1 "Drive" 0 "Free" ;
VAL_ 2566815905 RefOrd_2B_TM_Production_INF 1 "ON_Refer" 0 "OFF_Refer" ;
VAL_ 2566815905 RefOrd_0B1_TMProductionINF 1 "OFF_Refer" 0 "ON_Refer" ;
VAL_ 2565874085 TMProMsg2_67B_RatedPower 65535 "无效" 65534 "异常" ;
VAL_ 2565874085 TMProMsg2_45B_RatedTorq 65535 "无效" 65534 "异常" ;
VAL_ 2565874085 TMProMsg2_23B_TMPeakTorq 65535 "无效" 65534 "异常" ;
VAL_ 2565874085 TMProMsg2_01B_TMMaxSpd 65535 "无效" 65534 "异常" ;
VAL_ 2565873829 TMProMsg1_6B_TypeOfCooling 255 "其他方式" 2 "风冷" 1 "水冷" ;
VAL_ 2565873829 TMProMsg1_45B_TMPeakPower 65535 "无效" 65534 "异常" ;
VAL_ 2565873829 TMProMsg1_23B_MaxWorkingCur 65535 "无效" 65534 "异常" ;
VAL_ 2565873829 TMProMsg1_01B_RatedVoltage 65535 "无效" 65534 "异常" ;
